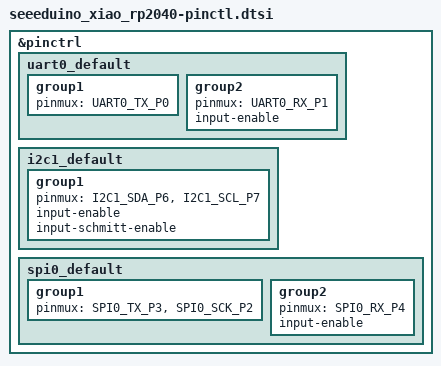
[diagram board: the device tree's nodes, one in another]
/*
 * Copyright (c) 2021, Yonatan Schachter
 * SPDX-License-Identifier: Apache-2.0
 */

#include <dt-bindings/pinctrl/rpi-pico-rp2040-pinctrl.h>

&pinctrl {
	uart0_default: uart0_default {
		group1 {
			pinmux = <UART0_TX_P0>;
		};
		group2 {
			pinmux = <UART0_RX_P1>;
			input-enable;
		};
	};

	i2c1_default: i2c1_default {
		group1 {
			pinmux = <I2C1_SDA_P6>, <I2C1_SCL_P7>;
			input-enable;
			input-schmitt-enable;
		};
	};

	spi0_default: spi0_default {
		group1 {
			pinmux = <SPI0_TX_P3>, <SPI0_SCK_P2>;
		};
		group2 {
			pinmux = <SPI0_RX_P4>;
			input-enable;
		};
	};
};
